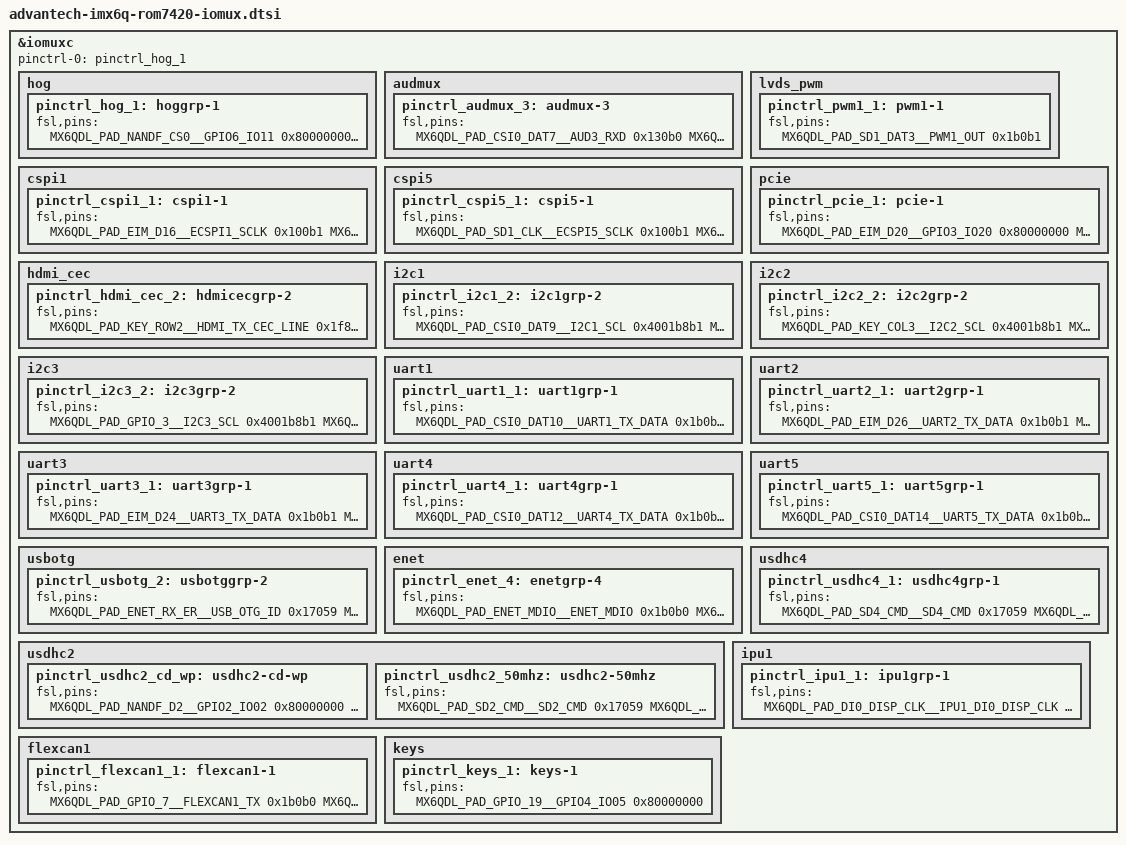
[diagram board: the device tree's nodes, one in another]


&iomuxc {
	pinctrl-names = "default";
	pinctrl-0 = <&pinctrl_hog_1>;

	hog {
		pinctrl_hog_1: hoggrp-1 {
			fsl,pins = <
				/* GPIO */
				MX6QDL_PAD_NANDF_CS0__GPIO6_IO11 			0x80000000	/* GPIO(171) start-stop-key*/
				MX6QDL_PAD_NANDF_CS1__GPIO6_IO14 			0x80000000	/* GPIO(174) print-key*/
				MX6QDL_PAD_NANDF_CS2__GPIO6_IO15 			0x80000000	/* GPIO(175) mode-key*/
				MX6QDL_PAD_NANDF_CS3__GPIO6_IO16 			0x80000000	/* GPIO(176) set-key*/
				MX6QDL_PAD_EIM_OE__GPIO2_IO25 				0x80000000	/* GPIO(57) clear-key*/
				MX6QDL_PAD_EIM_CS0__GPIO2_IO23 				0x80000000	/* GPIO(55) accumulation-key*/
				MX6QDL_PAD_EIM_CS1__GPIO2_IO24 				0x80000000	/* GPIO(56) gpio-7*/
				MX6QDL_PAD_EIM_A25__GPIO5_IO02 				0x80000000	/* GPIO(130) gpio-8*/
				MX6QDL_PAD_EIM_EB2__GPIO2_IO30 				0x80000000	/* GPIO(62) */
				MX6QDL_PAD_EIM_D19__GPIO3_IO19 				0x80000000	/* GPIO(83) CSPI1_CS1*/
				/* MX6QDL_PAD_EIM_D20__GPIO3_IO20 				0x80000000	GPIO(84) PCIE_PWR_EN*/
				MX6QDL_PAD_EIM_D22__GPIO3_IO22 				0x80000000	/* GPIO(86) OTG_PWR*/
				MX6QDL_PAD_EIM_D23__GPIO3_IO23 				0x80000000	/* GPIO(87) */
				MX6QDL_PAD_EIM_EB3__GPIO2_IO31 				0x80000000	/* GPIO(63) */
				MX6QDL_PAD_EIM_D30__GPIO3_IO30 				0x80000000	/* GPIO(94) BORAD_ID0*/
				MX6QDL_PAD_EIM_D31__GPIO3_IO31 				0x80000000	/* GPIO(95) BORAD_ID1*/
				MX6QDL_PAD_EIM_A24__GPIO5_IO04 				0x80000000	/* GPIO(132) */
				
				MX6QDL_PAD_EIM_A23__GPIO6_IO06 				0x80000000	/* GPIO(166) */
				MX6QDL_PAD_EIM_A22__GPIO2_IO16 				0x80000000	/* GPIO(48) */
				MX6QDL_PAD_EIM_A21__GPIO2_IO17 				0x80000000	/* GPIO(49) */
				MX6QDL_PAD_EIM_A20__GPIO2_IO18 				0x80000000	/* GPIO(50) */
				MX6QDL_PAD_EIM_A19__GPIO2_IO19 				0x80000000	/* GPIO(51) */
				MX6QDL_PAD_EIM_A18__GPIO2_IO20 				0x80000000	/* GPIO(52) */
				MX6QDL_PAD_EIM_A17__GPIO2_IO21 				0x80000000	/* GPIO(53) */
				MX6QDL_PAD_EIM_A16__GPIO2_IO22 				0x80000000	/* GPIO(54) */

				MX6QDL_PAD_EIM_RW__GPIO2_IO26 				0x80000000	/* GPIO(58) */
				MX6QDL_PAD_EIM_LBA__GPIO2_IO27 				0x80000000	/* GPIO(59) */
				MX6QDL_PAD_EIM_EB0__GPIO2_IO28 				0x80000000	/* GPIO(60) */
				MX6QDL_PAD_EIM_EB1__GPIO2_IO29 				0x80000000	/* GPIO(61) */
				MX6QDL_PAD_EIM_DA0__GPIO3_IO00 				0x80000000	/* GPIO(64) */
				MX6QDL_PAD_EIM_DA1__GPIO3_IO01 				0x80000000	/* GPIO(61) */
				MX6QDL_PAD_EIM_DA2__GPIO3_IO02 				0x80000000	/* GPIO(62) */
				MX6QDL_PAD_EIM_DA3__GPIO3_IO03 				0x80000000	/* GPIO(63) */
				MX6QDL_PAD_EIM_DA4__GPIO3_IO04 				0x80000000	/* GPIO(64) */
				
				MX6QDL_PAD_EIM_DA5__GPIO3_IO05 				0x80000000	/* GPIO(65) */
				MX6QDL_PAD_EIM_DA6__GPIO3_IO06 				0x80000000	/* GPIO(66) */
				MX6QDL_PAD_EIM_DA7__GPIO3_IO07 				0x80000000	/* GPIO(67) */
				MX6QDL_PAD_EIM_DA8__GPIO3_IO08 				0x80000000	/* GPIO(68) */
				MX6QDL_PAD_EIM_DA9__GPIO3_IO09 				0x80000000	/* GPIO(69) */
				MX6QDL_PAD_EIM_DA10__GPIO3_IO10 			0x80000000	/* GPIO(70) */
				MX6QDL_PAD_EIM_DA11__GPIO3_IO11 			0x80000000	/* GPIO(71) */
				MX6QDL_PAD_EIM_DA12__GPIO3_IO12 			0x80000000	/* GPIO(72) */
				MX6QDL_PAD_EIM_DA13__GPIO3_IO13 			0x80000000	/* GPIO(73) */
				MX6QDL_PAD_EIM_DA14__GPIO3_IO14 			0x80000000	/* GPIO(74) */
				
				MX6QDL_PAD_EIM_DA15__GPIO3_IO15 			0x80000000	/* GPIO(75) */
				MX6QDL_PAD_EIM_WAIT__GPIO5_IO00 			0x80000000	/* GPIO(128) */
				MX6QDL_PAD_ENET_TX_EN__GPIO1_IO28 			0x80000000	/* GPIO(28) */
				/* MX6QDL_PAD_KEY_COL4__GPIO4_IO14 			0x80000000	GPIO(110) PCIE_DIS_B*/
				/* MX6QDL_PAD_GPIO_17__GPIO7_IO12 				0x80000000	GPIO(204) PCIE_RST*/
				MX6QDL_PAD_GPIO_18__GPIO7_IO13 				0x80000000	/* GPIO(205) */
				/* MX6QDL_PAD_GPIO_19__GPIO4_IO05 				0x80000000	GPIO(101) KEY SLEEP*/
				/* MX6QDL_PAD_CSI0_DATA_EN__GPIO5_IO20 		0x80000000	GPIO(148) PCIE_WAKE_B*/
				
				MX6QDL_PAD_SD3_DAT7__GPIO6_IO17 			0x80000000	/* GPIO(177) */
				MX6QDL_PAD_SD3_DAT6__GPIO6_IO18 			0x80000000	/* GPIO(178) */
				MX6QDL_PAD_SD3_DAT5__GPIO7_IO00 			0x80000000	/* GPIO(192) */
				MX6QDL_PAD_SD3_DAT4__GPIO7_IO01 			0x80000000	/* GPIO(193) */
				MX6QDL_PAD_SD3_CMD__GPIO7_IO02 				0x80000000	/* GPIO(194) */
				MX6QDL_PAD_SD3_CLK__GPIO7_IO03 				0x80000000	/* GPIO(195) */
				MX6QDL_PAD_SD3_DAT0__GPIO7_IO04 			0x80000000	/* GPIO(196) MCU_SUSPEND_SINGAL*/
				MX6QDL_PAD_SD3_DAT1__GPIO7_IO05 			0x80000000	/* GPIO(197) MCU_SETUP_USB_SINGAL*/
				MX6QDL_PAD_SD3_DAT2__GPIO7_IO06 			0x80000000	/* GPIO(198) */
				MX6QDL_PAD_SD3_DAT3__GPIO7_IO07 			0x80000000	/* GPIO(199) */
				
				MX6QDL_PAD_NANDF_CLE__GPIO6_IO07 			0x80000000	/* GPIO(167) LCD_VDD_EN*/
				MX6QDL_PAD_NANDF_ALE__GPIO6_IO08 			0x80000000	/* GPIO(168) */
				MX6QDL_PAD_NANDF_WP_B__GPIO6_IO09 			0x80000000	/* GPIO(169) DISP0_WR_B*/
				/* MX6QDL_PAD_NANDF_CS0__GPIO6_IO11 			0x80000000	GPIO(171) start-stop-key*/
				/* MX6QDL_PAD_NANDF_CS1__GPIO6_IO14 			0x80000000	GPIO(174) print-key*/
				/* MX6QDL_PAD_NANDF_CS2__GPIO6_IO15 			0x80000000	GPIO(175) mode-key*/
				/* MX6QDL_PAD_NANDF_CS3__GPIO6_IO16 			0x80000000	GPIO(176) set-key*/
				/* MX6QDL_PAD_NANDF_D2__GPIO2_IO02 			0x80000000	GPIO(34) SD2_CD*/
				/* MX6QDL_PAD_NANDF_D3__GPIO2_IO03 			0x80000000	GPIO(35) SD2_WP*/
				MX6QDL_PAD_SD1_DAT1__GPIO1_IO17 			0x80000000	/* GPIO(17) CSPI5_CS0*/
				
				MX6QDL_PAD_SD1_DAT2__GPIO1_IO19 			0x80000000	/* GPIO(19) CSPI5_CS1*/

				MX6QDL_PAD_GPIO_0__CCM_CLKO1				0x130b0		/* SGTL5000 sys_mclk */
				
			>;
		};
	};

	audmux {
		pinctrl_audmux_3: audmux-3 {
			fsl,pins = <
				MX6QDL_PAD_CSI0_DAT7__AUD3_RXD				0x130b0
				MX6QDL_PAD_CSI0_DAT4__AUD3_TXC				0x130b0
				MX6QDL_PAD_CSI0_DAT5__AUD3_TXD				0x110b0
				MX6QDL_PAD_CSI0_DAT6__AUD3_TXFS				0x130b0
			>;
		};
	};

	lvds_pwm {
		pinctrl_pwm1_1: pwm1-1 {
			fsl,pins = <
				MX6QDL_PAD_SD1_DAT3__PWM1_OUT				0x1b0b1		/* LVDS_BLT_CTRL PWM */
			>;
		};
	};

	cspi1 {
		pinctrl_cspi1_1: cspi1-1 {
			fsl,pins = <
				MX6QDL_PAD_EIM_D16__ECSPI1_SCLK				0x100b1		/* CSPI1_CLK */
				MX6QDL_PAD_EIM_D17__ECSPI1_MISO				0x100b1		/* CSPI1_MISO */
				MX6QDL_PAD_EIM_D18__ECSPI1_MOSI				0x100b1		/* CSPI1_MOSI */
				/* MX6QDL_PAD_EIM_D19__GPIO3_IO19				0x100b1		CSPI1_CS0 */
			>;
		};
	};
	
	cspi5 {
		pinctrl_cspi5_1: cspi5-1 {
			fsl,pins = <
				MX6QDL_PAD_SD1_CLK__ECSPI5_SCLK				0x100b1		/* CSPI5_CLK */
				MX6QDL_PAD_SD1_DAT0__ECSPI5_MISO			0x100b1		/* CSPI5_MISO */
				MX6QDL_PAD_SD1_CMD__ECSPI5_MOSI				0x100b1		/* CSPI5_MOSI */
				/* MX6QDL_PAD_SD1_DAT1__GPIO1_IO17				0x100b1		CSPI5_CS0 */
				/* MX6QDL_PAD_SD1_DAT2__GPIO1_IO19				0x100b1		CSPI5_CS1 */
			>;
		};
	};
	
	pcie {
		pinctrl_pcie_1: pcie-1 {
			fsl,pins = <
				MX6QDL_PAD_EIM_D20__GPIO3_IO20				0x80000000	/* PCIE_PWR_EN */
				MX6QDL_PAD_GPIO_17__GPIO7_IO12				0x80000000	/* PCIE_RST */
				MX6QDL_PAD_CSI0_DATA_EN__GPIO5_IO20			0x80000000	/* PCIE_WAKE_B */
				MX6QDL_PAD_KEY_COL4__GPIO4_IO14				0x80000000	/* PCIE_DIS_B */
			>;
		};
	};

	hdmi_cec {
		pinctrl_hdmi_cec_2: hdmicecgrp-2 {
			fsl,pins = <
				MX6QDL_PAD_KEY_ROW2__HDMI_TX_CEC_LINE 		0x1f8b0
			>;
		};
	};

	i2c1 {
		pinctrl_i2c1_2: i2c1grp-2 {
			fsl,pins = <
				MX6QDL_PAD_CSI0_DAT9__I2C1_SCL 				0x4001b8b1
				MX6QDL_PAD_CSI0_DAT8__I2C1_SDA 				0x4001b8b1
			>;
		};
	};

	i2c2 {
		pinctrl_i2c2_2: i2c2grp-2 {
			fsl,pins = <
				MX6QDL_PAD_KEY_COL3__I2C2_SCL 				0x4001b8b1
				MX6QDL_PAD_KEY_ROW3__I2C2_SDA 				0x4001b8b1
			>;
		};
	};

	i2c3 {
		pinctrl_i2c3_2: i2c3grp-2 {
			fsl,pins = <
				MX6QDL_PAD_GPIO_3__I2C3_SCL 				0x4001b8b1
				MX6QDL_PAD_GPIO_6__I2C3_SDA 				0x4001b8b1
			>;
		};
	};

	uart1 {
		pinctrl_uart1_1: uart1grp-1 {
			fsl,pins = <
				MX6QDL_PAD_CSI0_DAT10__UART1_TX_DATA 		0x1b0b1
				MX6QDL_PAD_CSI0_DAT11__UART1_RX_DATA 		0x1b0b1
			>;
		};		
	};

	uart2 {
		pinctrl_uart2_1: uart2grp-1 {
			fsl,pins = <
				MX6QDL_PAD_EIM_D26__UART2_TX_DATA 		0x1b0b1
				MX6QDL_PAD_EIM_D27__UART2_RX_DATA 		0x1b0b1
			>;
		};		
	};

	uart3 {
		pinctrl_uart3_1: uart3grp-1 {
			fsl,pins = <
				MX6QDL_PAD_EIM_D24__UART3_TX_DATA 			0x1b0b1
				MX6QDL_PAD_EIM_D25__UART3_RX_DATA 			0x1b0b1
			>;
		};		
	};

	uart4 {
		pinctrl_uart4_1: uart4grp-1 {
			fsl,pins = <
				MX6QDL_PAD_CSI0_DAT12__UART4_TX_DATA 		0x1b0b1
				MX6QDL_PAD_CSI0_DAT13__UART4_RX_DATA 		0x1b0b1
			>;
		};		
	};

	uart5 {
		/* DTE mode */
		pinctrl_uart5_1: uart5grp-1 {
			fsl,pins = <
				MX6QDL_PAD_CSI0_DAT14__UART5_TX_DATA		0x1b0b1
				MX6QDL_PAD_CSI0_DAT15__UART5_RX_DATA		0x1b0b1
			>;
		};
	};

	usbotg {
		pinctrl_usbotg_2: usbotggrp-2 {
			fsl,pins = <
				MX6QDL_PAD_ENET_RX_ER__USB_OTG_ID			0x17059		/* USB_OTG_ID */
				MX6QDL_PAD_KEY_ROW4__USB_OTG_PWR			0x000b0		/* USB_OTG_PWR */
				MX6QDL_PAD_EIM_D21__USB_OTG_OC				0x1b0b0		/* USB_OTG_OC */
			>;
		};
	};

	enet {
		pinctrl_enet_4: enetgrp-4 {
			fsl,pins = <
				MX6QDL_PAD_ENET_MDIO__ENET_MDIO				0x1b0b0		/* RGMII_MDIO */
				MX6QDL_PAD_ENET_MDC__ENET_MDC				0x1b0b0		/* RGMII_MDC */
				MX6QDL_PAD_RGMII_TXC__RGMII_TXC				0x1b0b0
				MX6QDL_PAD_RGMII_TD0__RGMII_TD0				0x1b0b0
				MX6QDL_PAD_RGMII_TD1__RGMII_TD1				0x1b0b0
				MX6QDL_PAD_RGMII_TD2__RGMII_TD2				0x1b0b0
				MX6QDL_PAD_RGMII_TD3__RGMII_TD3				0x1b0b0
				MX6QDL_PAD_RGMII_TX_CTL__RGMII_TX_CTL		0x1b0b0
				MX6QDL_PAD_ENET_REF_CLK__ENET_TX_CLK		0x0a0b1		/* ENET_REFCLK */
				MX6QDL_PAD_RGMII_RXC__RGMII_RXC				0x1b0b0
				MX6QDL_PAD_RGMII_RD0__RGMII_RD0				0x1b0b0
				MX6QDL_PAD_RGMII_RD1__RGMII_RD1				0x1b0b0
				MX6QDL_PAD_RGMII_RD2__RGMII_RD2				0x1b0b0
				MX6QDL_PAD_RGMII_RD3__RGMII_RD3				0x1b0b0
				MX6QDL_PAD_RGMII_RX_CTL__RGMII_RX_CTL		0x1b0b0
				MX6QDL_PAD_ENET_CRS_DV__GPIO1_IO25 			0x80000000	/* GPIO(25) RGMII_nRST*/
				MX6QDL_PAD_ENET_RXD1__GPIO1_IO26 			0x80000000	/* GPIO(26) RGMII_INT*/
			>;
		};
	};

	usdhc2 {
		pinctrl_usdhc2_cd_wp: usdhc2-cd-wp {
			fsl,pins = <
				MX6QDL_PAD_NANDF_D2__GPIO2_IO02				0x80000000	/* SD2_CD */
				MX6QDL_PAD_NANDF_D3__GPIO2_IO03				0x80000000	/* SD2_WP */
			>;
		};
		
		pinctrl_usdhc2_50mhz: usdhc2-50mhz {					/* 50Mhz */
			fsl,pins = <
				MX6QDL_PAD_SD2_CMD__SD2_CMD					0x17059
				MX6QDL_PAD_SD2_CLK__SD2_CLK					0x10059
				MX6QDL_PAD_SD2_DAT0__SD2_DATA0				0x17059
				MX6QDL_PAD_SD2_DAT1__SD2_DATA1				0x17059
				MX6QDL_PAD_SD2_DAT2__SD2_DATA2				0x17059
				MX6QDL_PAD_SD2_DAT3__SD2_DATA3				0x17059
			>;
		};
	};

	usdhc4 {
		pinctrl_usdhc4_1: usdhc4grp-1 {
			fsl,pins = <
				MX6QDL_PAD_SD4_CMD__SD4_CMD    				0x17059
				MX6QDL_PAD_SD4_CLK__SD4_CLK    				0x10059
				MX6QDL_PAD_SD4_DAT0__SD4_DATA0 				0x17059
				MX6QDL_PAD_SD4_DAT1__SD4_DATA1 				0x17059
				MX6QDL_PAD_SD4_DAT2__SD4_DATA2 				0x17059
				MX6QDL_PAD_SD4_DAT3__SD4_DATA3 				0x17059
				MX6QDL_PAD_SD4_DAT4__SD4_DATA4 				0x17059
				MX6QDL_PAD_SD4_DAT5__SD4_DATA5 				0x17059
				MX6QDL_PAD_SD4_DAT6__SD4_DATA6 				0x17059
				MX6QDL_PAD_SD4_DAT7__SD4_DATA7 				0x17059
			>;
		};
	};

	ipu1 {
		pinctrl_ipu1_1: ipu1grp-1 {
			fsl,pins = <
				MX6QDL_PAD_DI0_DISP_CLK__IPU1_DI0_DISP_CLK 	0x10
				MX6QDL_PAD_DI0_PIN15__IPU1_DI0_PIN15       	0x10
				MX6QDL_PAD_DI0_PIN2__IPU1_DI0_PIN02        	0x10
				MX6QDL_PAD_DI0_PIN3__IPU1_DI0_PIN03        	0x10
				MX6QDL_PAD_DI0_PIN4__IPU1_DI0_PIN04        	0x10
				MX6QDL_PAD_DISP0_DAT0__IPU1_DISP0_DATA00   	0x10
				MX6QDL_PAD_DISP0_DAT1__IPU1_DISP0_DATA01   	0x10
				MX6QDL_PAD_DISP0_DAT2__IPU1_DISP0_DATA02   	0x10
				MX6QDL_PAD_DISP0_DAT3__IPU1_DISP0_DATA03   	0x10
				MX6QDL_PAD_DISP0_DAT4__IPU1_DISP0_DATA04   	0x10
				MX6QDL_PAD_DISP0_DAT5__IPU1_DISP0_DATA05   	0x10
				MX6QDL_PAD_DISP0_DAT6__IPU1_DISP0_DATA06   	0x10
				MX6QDL_PAD_DISP0_DAT7__IPU1_DISP0_DATA07   	0x10
				MX6QDL_PAD_DISP0_DAT8__IPU1_DISP0_DATA08   	0x10
				MX6QDL_PAD_DISP0_DAT9__IPU1_DISP0_DATA09   	0x10
				MX6QDL_PAD_DISP0_DAT10__IPU1_DISP0_DATA10  	0x10
				MX6QDL_PAD_DISP0_DAT11__IPU1_DISP0_DATA11  	0x10
				MX6QDL_PAD_DISP0_DAT12__IPU1_DISP0_DATA12  	0x10
				MX6QDL_PAD_DISP0_DAT13__IPU1_DISP0_DATA13  	0x10
				MX6QDL_PAD_DISP0_DAT14__IPU1_DISP0_DATA14  	0x10
				MX6QDL_PAD_DISP0_DAT15__IPU1_DISP0_DATA15  	0x10
				MX6QDL_PAD_DISP0_DAT16__IPU1_DISP0_DATA16  	0x10
				MX6QDL_PAD_DISP0_DAT17__IPU1_DISP0_DATA17  	0x10
				MX6QDL_PAD_DISP0_DAT18__IPU1_DISP0_DATA18  	0x10
				MX6QDL_PAD_DISP0_DAT19__IPU1_DISP0_DATA19  	0x10
				MX6QDL_PAD_DISP0_DAT20__IPU1_DISP0_DATA20  	0x10
				MX6QDL_PAD_DISP0_DAT21__IPU1_DISP0_DATA21  	0x10
				MX6QDL_PAD_DISP0_DAT22__IPU1_DISP0_DATA22  	0x10
				MX6QDL_PAD_DISP0_DAT23__IPU1_DISP0_DATA23  	0x10
			>;
		};
	};

	flexcan1 {
		pinctrl_flexcan1_1: flexcan1-1 {
			fsl,pins = <
				MX6QDL_PAD_GPIO_7__FLEXCAN1_TX				0x1b0b0		/* CAN1_TX */
				MX6QDL_PAD_GPIO_8__FLEXCAN1_RX				0x1b0b0		/* CAN1_RX */
			>;
		};
	};

	keys {
		pinctrl_keys_1: keys-1 {
			fsl,pins = <	
				/* special key */
				MX6QDL_PAD_GPIO_19__GPIO4_IO05 				0x80000000	/* GPIO(101) KEY SLEEP*/
			>;
		};
	};		

};

